# STM32H730 register map
File version: 1.2
CPU: CM7 r0p1, little endian, MPU, FPU, 4 interrupt priority bits
Registers are 32-bit, read-write, reset 0x0 unless marked. A register's access mark holds for its fields unless they carry their own. Offsets are from the block's base; [hi:lo] are bit positions; 'fields as' and 'values as' point back to an identical list.

## CRS — Clock Recovery System
Base 0x40008400
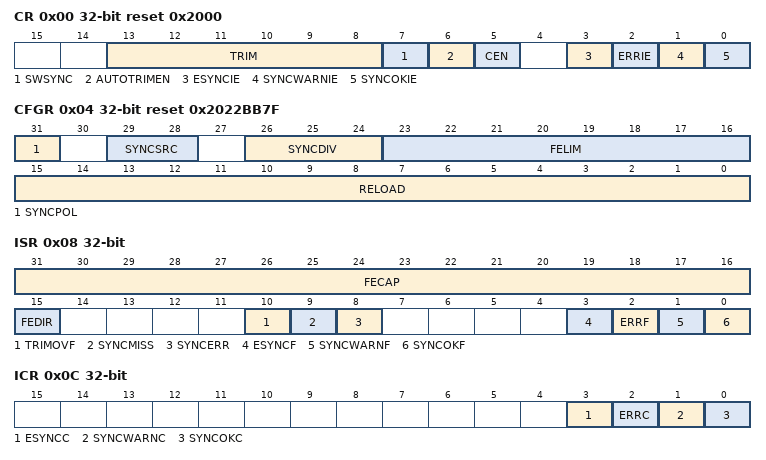
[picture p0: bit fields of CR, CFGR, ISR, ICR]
0x00 CR access per field reset 0x2000 — CRS control register
  [13:8] TRIM rw — HSI48 oscillator smooth trimming These bits provide a user-programmable trimming value to the HSI48 oscillator. They can be programmed to adjust to variations in voltage and temperature that influence the frequency of the HSI48. The default value is 32, which corresponds to the middle of the trimming interval. The trimming step is around 67 kHz between two consecutive TRIM steps. A higher TRIM value corresponds to a higher output frequency. When the AUTOTRIMEN bit is set, this field is controlled by hardware and is read-only.
  [7] SWSYNC ro — Generate software SYNC event This bit is set by software in order to generate a software SYNC event. It is automatically cleared by hardware.
    1=Sync (A software sync is generated)
  [6] AUTOTRIMEN rw — Automatic trimming enable This bit enables the automatic hardware adjustment of TRIM bits according to the measured frequency error between two SYNC events. If this bit is set, the TRIM bits are read-only. The TRIM value can be adjusted by hardware by one or two steps at a time, depending on the measured frequency error value. Refer to Section7.3.4: Frequency error evaluation and automatic trimming for more details.
    0=Disabled (Automatic trimming disabled); 1=Enabled (Automatic trimming enabled)
  [5] CEN rw — Frequency error counter enable This bit enables the oscillator clock for the frequency error counter. When this bit is set, the CRS_CFGR register is write-protected and cannot be modified.
    0=Disabled (Frequency error counter disabled); 1=Enabled (Frequency error counter enabled)
  [3] ESYNCIE rw — Expected SYNC interrupt enable
    0=Disabled (Interrupt disabled); 1=Enabled (Interrupt enabled)
  [2] ERRIE rw — Synchronization or trimming error interrupt enable
    values as ESYNCIE
  [1] SYNCWARNIE rw — SYNC warning interrupt enable
    values as ESYNCIE
  [0] SYNCOKIE rw — SYNC event OK interrupt enable
    values as ESYNCIE
0x04 CFGR reset 0x2022BB7F — This register can be written only when the frequency error counter is disabled (CEN bit is cleared in CRS_CR). When the counter is enabled, this register is write-protected.
  [31] SYNCPOL — SYNC polarity selection This bit is set and cleared by software to select the input polarity for the SYNC signal source.
    0=RisingEdge (SYNC active on rising edge); 1=FallingEdge (SYNC active on falling edge)
  [29:28] SYNCSRC — SYNC signal source selection These bits are set and cleared by software to select the SYNC signal source. Note: When using USB LPM (Link Power Management) and the device is in Sleep mode, the periodic USB SOF will not be generated by the host. No SYNC signal will therefore be provided to the CRS to calibrate the HSI48 on the run. To guarantee the required clock precision after waking up from Sleep mode, the LSE or reference clock on the GPIOs should be used as SYNC signal.
    0=GPIO_AF (GPIO AF (crs_sync_in_1) selected as SYNC signal source); 1=LSE (LSE (crs_sync_in_2) selected as SYNC signal source); 2=USB_SOF (USB SOF (crs_sync_in_3) selected as SYNC signal source)
  [26:24] SYNCDIV — SYNC divider These bits are set and cleared by software to control the division factor of the SYNC signal.
    0=Div1 (SYNC not divided); 1=Div2 (SYNC divided by 2); 2=Div4 (SYNC divided by 4); 3=Div8 (SYNC divided by 8); 4=Div16 (SYNC divided by 16); 5=Div32 (SYNC divided by 32); 6=Div64 (SYNC divided by 64); 7=Div128 (SYNC divided by 128)
  [23:16] FELIM — Frequency error limit FELIM contains the value to be used to evaluate the captured frequency error value latched in the FECAP[15:0] bits of the CRS_ISR register. Refer to Section7.3.4: Frequency error evaluation and automatic trimming for more details about FECAP evaluation.
  [15:0] RELOAD — Counter reload value RELOAD is the value to be loaded in the frequency error counter with each SYNC event. Refer to Section7.3.3: Frequency error measurement for more details about counter behavior.
0x08 ISR ro — CRS interrupt and status register
  [31:16] FECAP — Frequency error capture FECAP is the frequency error counter value latched in the time of the last SYNC event. Refer to Section7.3.4: Frequency error evaluation and automatic trimming for more details about FECAP usage.
  [15] FEDIR — Frequency error direction FEDIR is the counting direction of the frequency error counter latched in the time of the last SYNC event. It shows whether the actual frequency is below or above the target.
    0=UpCounting (Error in up-counting direction); 1=DownCounting (Error in down-counting direction)
  [10] TRIMOVF — Trimming overflow or underflow This flag is set by hardware when the automatic trimming tries to over- or under-flow the TRIM value. An interrupt is generated if the ERRIE bit is set in the CRS_CR register. It is cleared by software by setting the ERRC bit in the CRS_ICR register.
    0=NotSignaled (Signal not set); 1=Signaled (Signal set)
  [9] SYNCMISS — SYNC missed This flag is set by hardware when the frequency error counter reached value FELIM * 128 and no SYNC was detected, meaning either that a SYNC pulse was missed or that the frequency error is too big (internal frequency too high) to be compensated by adjusting the TRIM value, and that some other action should be taken. At this point, the frequency error counter is stopped (waiting for a next SYNC) and an interrupt is generated if the ERRIE bit is set in the CRS_CR register. It is cleared by software by setting the ERRC bit in the CRS_ICR register.
    0=NotSignaled (Signal not set); 1=Signaled (Signal set)
  [8] SYNCERR — SYNC error This flag is set by hardware when the SYNC pulse arrives before the ESYNC event and the measured frequency error is greater than or equal to FELIM * 128. This means that the frequency error is too big (internal frequency too low) to be compensated by adjusting the TRIM value, and that some other action should be taken. An interrupt is generated if the ERRIE bit is set in the CRS_CR register. It is cleared by software by setting the ERRC bit in the CRS_ICR register.
    0=NotSignaled (Signal not set); 1=Signaled (Signal set)
  [3] ESYNCF — Expected SYNC flag This flag is set by hardware when the frequency error counter reached a zero value. An interrupt is generated if the ESYNCIE bit is set in the CRS_CR register. It is cleared by software by setting the ESYNCC bit in the CRS_ICR register.
    0=NotSignaled (Signal not set); 1=Signaled (Signal set)
  [2] ERRF — Error flag This flag is set by hardware in case of any synchronization or trimming error. It is the logical OR of the TRIMOVF, SYNCMISS and SYNCERR bits. An interrupt is generated if the ERRIE bit is set in the CRS_CR register. It is cleared by software in reaction to setting the ERRC bit in the CRS_ICR register, which clears the TRIMOVF, SYNCMISS and SYNCERR bits.
    0=NotSignaled (Signal not set); 1=Signaled (Signal set)
  [1] SYNCWARNF — SYNC warning flag This flag is set by hardware when the measured frequency error is greater than or equal to FELIM * 3, but smaller than FELIM * 128. This means that to compensate the frequency error, the TRIM value must be adjusted by two steps or more. An interrupt is generated if the SYNCWARNIE bit is set in the CRS_CR register. It is cleared by software by setting the SYNCWARNC bit in the CRS_ICR register.
    0=NotSignaled (Signal not set); 1=Signaled (Signal set)
  [0] SYNCOKF — SYNC event OK flag This flag is set by hardware when the measured frequency error is smaller than FELIM * 3. This means that either no adjustment of the TRIM value is needed or that an adjustment by one trimming step is enough to compensate the frequency error. An interrupt is generated if the SYNCOKIE bit is set in the CRS_CR register. It is cleared by software by setting the SYNCOKC bit in the CRS_ICR register.
    0=NotSignaled (Signal not set); 1=Signaled (Signal set)
0x0C ICR — CRS interrupt flag clear register
  [all] fields
    1=Clear flag
  [3] ESYNCC — Expected SYNC clear flag Writing 1 to this bit clears the ESYNCF flag in the CRS_ISR register.
  [2] ERRC — Error clear flag Writing 1 to this bit clears TRIMOVF, SYNCMISS and SYNCERR bits and consequently also the ERRF flag in the CRS_ISR register.
  [1] SYNCWARNC — SYNC warning clear flag Writing 1 to this bit clears the SYNCWARNF flag in the CRS_ISR register.
  [0] SYNCOKC — SYNC event OK clear flag Writing 1 to this bit clears the SYNCOKF flag in the CRS_ISR register.
